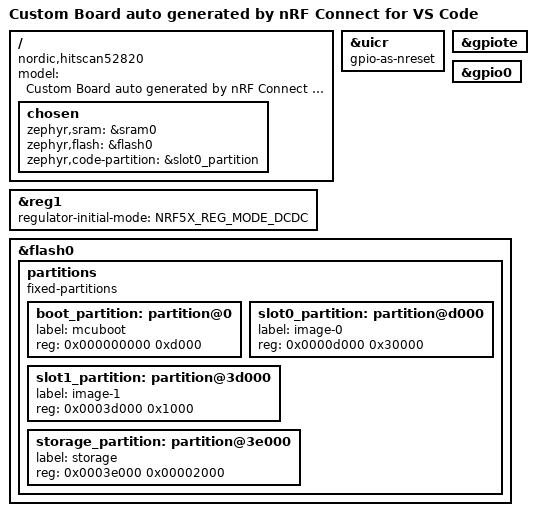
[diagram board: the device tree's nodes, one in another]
/dts-v1/;
#include <nordic/nrf52820_qdaa.dtsi>
#include "hitscan52820-pinctrl.dtsi"

/ {
	model = "Custom Board auto generated by nRF Connect for VS Code";
	compatible = "nordic,hitscan52820";

	chosen {
		zephyr,sram = &sram0;
		zephyr,flash = &flash0;
		zephyr,code-partition = &slot0_partition;
	};
};

&reg1 {
	regulator-initial-mode = <NRF5X_REG_MODE_DCDC>;
};

&uicr {
	gpio-as-nreset;
};

&gpiote {
	status = "okay";
};

&gpio0 {
	status = "okay";
};

&flash0 {
	/*
	 * For more information, see:
	 * http://docs.zephyrproject.org/latest/guides/dts/index.html#flash-partitions
	 */
	partitions {
		compatible = "fixed-partitions";
		#address-cells = <1>;
		#size-cells = <1>;

		boot_partition: partition@0 {
			label = "mcuboot";
			reg = <0x000000000 0xd000>;
		};
		slot0_partition: partition@d000 {
			label = "image-0";
			reg = <0x0000d000 0x30000>;
		};
		slot1_partition: partition@3d000 {
			label = "image-1";
			reg = <0x0003d000 0x1000>;
		};
		storage_partition: partition@3e000 {
			label = "storage";
			reg = <0x0003e000 0x00002000>;
		};
	};
};

// zephyr_udc0: &usbd {
// 	compatible = "nordic,nrf-usbd";
// 	status = "okay";
// };

